# MKW21D5 register map
Vendor: Freescale Semiconductor, Inc.; Series: Kinetis_W; File version: 1.6
CPU: CM4 r0p1, little endian, no MPU, no FPU, VTOR, 4 interrupt priority bits
Registers are 32-bit, read-write, reset 0x0 unless marked. A register's access mark holds for its fields unless they carry their own. Offsets are from the block's base; [hi:lo] are bit positions; {n}, {i} and the like mark numbered series.

## SMC — System Mode Controller
Base 0x4007E000; register names take the prefix SMC_
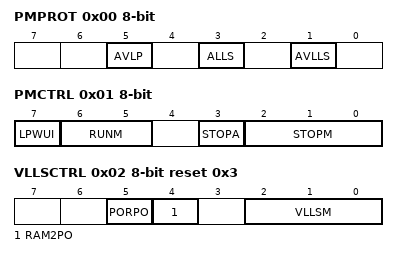
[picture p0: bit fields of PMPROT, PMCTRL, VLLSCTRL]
0x00 PMPROT 8-bit — Power Mode Protection register
  [5] AVLP — Allow Very-Low-Power Modes
    0=VLPR, VLPW and VLPS are not allowed; 1=VLPR, VLPW and VLPS are allowed
  [3] ALLS — Allow Low-Leakage Stop Mode
    0=Any LLSx mode is not allowed; 1=Any LLSx mode is allowed
  [1] AVLLS — Allow Very-Low-Leakage Stop Mode
    0=Any VLLSx mode is not allowed; 1=Any VLLSx mode is allowed
0x01 PMCTRL 8-bit — Power Mode Control register
  [7] LPWUI — Low-Power Wake Up On Interrupt
    0=The system remains in a VLP mode on an interrupt; 1=The system exits to Normal RUN mode on an interrupt
  [6:5] RUNM — Run Mode Control
    0=Normal Run mode (RUN); 2=Very-Low-Power Run mode (VLPR)
  [3] STOPA ro — Stop Aborted
    0=The previous stop mode entry was successsful; 1=The previous stop mode entry was aborted
  [2:0] STOPM — Stop Mode Control
    0=Normal Stop (STOP); 2=Very-Low-Power Stop (VLPS); 3=Low-Leakage Stop (LLSx); 4=Very-Low-Leakage Stop (VLLSx); 6=Reseved
0x02 VLLSCTRL 8-bit reset 0x3 — VLLS Control register
  [5] PORPO — POR Power Option
    0=POR detect circuit is enabled in VLLS0; 1=POR detect circuit is disabled in VLLS0
  [4] RAM2PO — RAM2 Power Option
    0=RAM2 not powered in VLLS2; 1=RAM2 powered in VLLS2
  [2:0] VLLSM — VLLS Mode Control
    {v}=VLLS{v} (v=0..3)
0x03 PMSTAT 8-bit ro reset 0x1 — Power Mode Status register
  [6:0] PMSTAT — When debug is enabled, the PMSTAT will not update to STOP or VLPS

## RCM — Reset Control Module
Base 0x4007F000; register names take the prefix RCM_
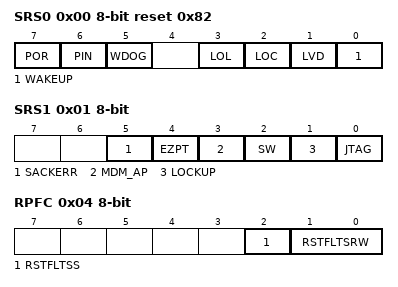
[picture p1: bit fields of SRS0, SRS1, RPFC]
0x00 SRS0 8-bit ro reset 0x82 — System Reset Status Register 0
  [7] POR — Power-On Reset
    0=Reset not caused by POR; 1=Reset caused by POR
  [6] PIN — External Reset Pin
    0=Reset not caused by external reset pin; 1=Reset caused by external reset pin
  [5] WDOG — Watchdog
    0=Reset not caused by watchdog timeout; 1=Reset caused by watchdog timeout
  [3] LOL — Loss-of-Lock Reset
    0=Reset not caused by a loss of lock in the PLL; 1=Reset caused by a loss of lock in the PLL
  [2] LOC — Loss-of-Clock Reset
    0=Reset not caused by a loss of external clock; 1=Reset caused by a loss of external clock
  [1] LVD — Low-Voltage Detect Reset
    0=Reset not caused by LVD trip or POR; 1=Reset caused by LVD trip or POR
  [0] WAKEUP — Low Leakage Wakeup Reset
    0=Reset not caused by LLWU module wakeup source; 1=Reset caused by LLWU module wakeup source
0x01 SRS1 8-bit ro — System Reset Status Register 1
  [5] SACKERR — Stop Mode Acknowledge Error Reset
    0=Reset not caused by peripheral failure to acknowledge attempt to enter stop mode; 1=Reset caused by peripheral failure to acknowledge attempt to enter stop mode
  [4] EZPT — EzPort Reset
    0=Reset not caused by EzPort receiving the RESET command while the device is in EzPort mode; 1=Reset caused by EzPort receiving the RESET command while the device is in EzPort mode
  [3] MDM_AP — MDM-AP System Reset Request
    0=Reset not caused by host debugger system setting of the System Reset Request bit; 1=Reset caused by host debugger system setting of the System Reset Request bit
  [2] SW — Software
    0=Reset not caused by software setting of SYSRESETREQ bit; 1=Reset caused by software setting of SYSRESETREQ bit
  [1] LOCKUP — Core Lockup
    0=Reset not caused by core LOCKUP event; 1=Reset caused by core LOCKUP event
  [0] JTAG — JTAG Generated Reset
    0=Reset not caused by JTAG; 1=Reset caused by JTAG
0x04 RPFC 8-bit — Reset Pin Filter Control register
  [2] RSTFLTSS — Reset Pin Filter Select in Stop Mode
    0=All filtering disabled; 1=LPO clock filter enabled
  [1:0] RSTFLTSRW — Reset Pin Filter Select in Run and Wait Modes
    0=All filtering disabled; 1=Bus clock filter enabled for normal operation; 2=LPO clock filter enabled for normal operation
0x05 RPFW 8-bit — Reset Pin Filter Width register
  [4:0] RSTFLTSEL — Reset Pin Filter Bus Clock Select
    {v}=Bus clock filter count is {v+1} (v=0..31)
0x07 MR 8-bit ro — Mode Register
  [1] EZP_MS — EZP_MS_B pin state
    0=Pin deasserted (logic 1); 1=Pin asserted (logic 0)
